# TC37XPD register map
Vendor: Infineon; Series: ATVMC; File version: 100
CPU: other r0p0, little endian, MPU, FPU, vendor SysTick, 4 interrupt priority bits
Registers are 32-bit, read-write, reset 0x0 unless marked. A register's access mark holds for its fields unless they carry their own. Offsets are from the block's base; [hi:lo] are bit positions; lines under a group give offsets from that group; {n}, {i} and the like mark numbered series.

## GTM (part 2 of 13)
Base 0xF0100000
0x400 BRC group
  {0x0+8j} SRC[{j}] (j=0..11) group
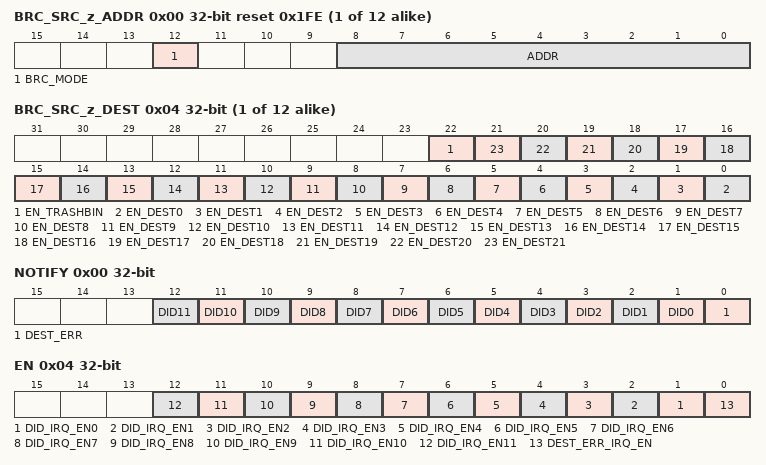
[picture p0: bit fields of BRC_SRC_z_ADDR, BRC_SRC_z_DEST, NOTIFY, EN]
    0x00 BRC_SRC_z_ADDR reset 0x1FE — BRC Read Address for Input Channel 0 resetvalue={Application Reset:0x1FE}
      [12] BRC_MODE — BRC MODE BRC Operation mode select. This bit field is only writable if channel is disabled.
      [8:0] ADDR — Source ARU address. Defines an ARU read address used as data source for input channel z. This bit field is only writable if channel is disabled.
    0x04 BRC_SRC_z_DEST — BRC Destination Channels for Input Channel 0 resetvalue={Application Reset:0x0}
      [22] EN_TRASHBIN — EN TRASHBIN Control trash bin functionality. When bit EN TRASHBIN is enabled bits 0 to 21 are ignored for this input channel. Therefore the bits 0 to 21 are set to zero 0 when trash bin functionality is enabled.
      [n] EN_DEST{n} (n=0..21) — Enable BRC destination address q. The bits 0 to 21 are cleared by auto correction mechanism if a destination channel is assigned to multiple source channels. When a BRC input channel is disabled all EN DESTq q 0...21 bits are reset to zero the internal states are reset to their reset value.
  0x60 IRQ group
    0x00 NOTIFY — BRC Interrupt Notification Register resetvalue={Application Reset:0x0}
      [n+1] DID{n} (n=0..11) — Data inconsistency occurred for channel x in MTM mode. This bit will be cleared on a CPU write access of value 1 . A read access leaves the bit unchanged.
      [0] DEST_ERR — Configuration error interrupt for BRC sub module. This bit will be cleared on a CPU write access of value 1 . As the bit is rw otherwise no clear. A read access leaves the bit unchanged.
    0x04 EN — BRC Interrupt Enable Register resetvalue={Application Reset:0x0}
      [n+1] DID_IRQ_EN{n} (n=0..11) — Enable DID interrupt for channel x
      [0] DEST_ERR_IRQ_EN — BRC DEST ERR IRQ interrupt enable
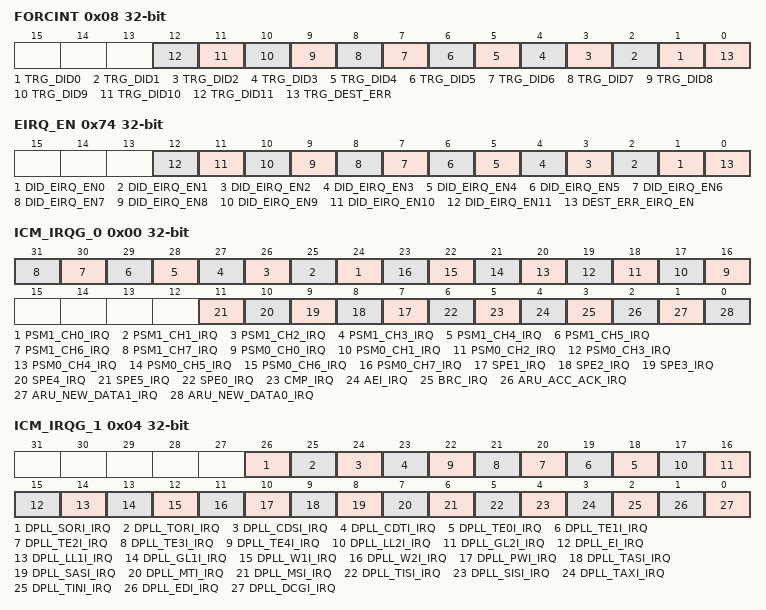
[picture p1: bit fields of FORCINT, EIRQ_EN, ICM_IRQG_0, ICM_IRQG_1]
    0x08 FORCINT — BRC Force Interrupt Register resetvalue={Application Reset:0x0}
      [n+1] TRG_DID{n} (n=0..11) — Trigger DID interrupt for channel x. This bit is cleared automatically after write. This bit is write protected by bit RF PROT of register GTM CTRL.
      [0] TRG_DEST_ERR — Trigger destination error interrupt. This bit is cleared automatically after write. This bit is write protected by bit RF PROT of register GTM CTRL.
    0x0C MODE — BRC Interrupt Mode Configuration Register resetvalue={Application Reset:0x0}
      [1:0] IRQ_MODE — IRQ mode selection. Note The interrupt modes are described in CROSSREFERENCE .
  0x70 RST — BRC Software Reset Register resetvalue={Application Reset:0x0}
    [0] RST — Software reset. This bit is cleared automatically after write by CPU. The channel registers are set to their reset values and channel operation is stopped immediately.
  0x74 EIRQ_EN — BRC Error Interrupt Enable Register resetvalue={Application Reset:0x0}
    [n+1] DID_EIRQ_EN{n} (n=0..11) — Enable DID interrupt for channel x
    [0] DEST_ERR_EIRQ_EN — BRC DEST ERR EIRQ error interrupt enable
0x600 ICM group
  0x00 IRQG group
    0x00 ICM_IRQG_0 ro — ICM Interrupt Group Register Covering Infrastructural and Safety Components ARU BRC AEI PSM0 PSM1 MAP CMP SPE resetvalue={Application Reset:0x0}
      [n+24] PSM1_CH{n}_IRQ (n=0..7) — PSM1 shared sub module channel 7 interrupt. See bit 0 and bit 6. Set this bit represents an OR function of the four interrupt sources FIFO EMPTY FIFO FULL FIFO LOWER WM or FIFO UPPER WM of FIFO instance 1 channel x.
      [n+16] PSM0_CH{n}_IRQ (n=0..7) — PSM0 shared sub module channel 7 interrupt. See bit 0 and bit 6. Set this bit represents an OR function of the four interrupt sources FIFO EMPTY FIFO FULL FIFO LOWER WM or FIFO UPPER WM of FIFO instance 0 channel x.
      [n+6] SPE{n}_IRQ (n=1..5) — SPE{n} shared sub module interrupt. See bit 0 and bit 6.
      [6] SPE0_IRQ — SPE0 shared sub module interrupt. Bit coding see bit 0. Set this bit represents an OR function of the five interrupt sources SPE NIPD SPE DCHG SPE PERR SPE BIS or SPE RCMP of SPE instance 0.
      [5] CMP_IRQ — CMP shared sub module interrupt. Bit coding see bit 0.
      [4] AEI_IRQ — AEI IRQ interrupt. Bit coding see bit 0. Set this bit represents an OR function of the seven interrupt sources AEI TO XPT AEI USP ADDR AEI IM ADDR AEI USP BE AEIM USP ADDR AEIM IM ADDR or AEIM USP BE .
      [3] BRC_IRQ — BRC shared sub module interrupt. Bit coding see bit 0.
      [2] ARU_ACC_ACK_IRQ — ARU ACC ACK interrupt. Bit coding see bit 0.
      [1] ARU_NEW_DATA1_IRQ — ARU NEW DATA1 interrupt. Bit coding see bit 0.
      [0] ARU_NEW_DATA0_IRQ — ARU NEW DATA0 interrupt. This bit is only set when the interrupt is enabled in the interrupt enable register of the corresponding sub module.
    0x04 ICM_IRQG_1 ro — ICM Interrupt Group Register Covering DPLL resetvalue={Application Reset:0x0}
      [26] DPLL_SORI_IRQ — DPLL calculated duration interrupt for state. Bit coding see bit 0.
      [25] DPLL_TORI_IRQ — DPLL calculated duration interrupt for state. Bit coding see bit 0.
      [24] DPLL_CDSI_IRQ — DPLL calculated duration interrupt for state. Bit coding see bit 0.
      [23] DPLL_CDTI_IRQ — DPLL calculated duration interrupt for trigger. Bit coding see bit 0.
      [n+18] DPLL_TE{n}I_IRQ (n=0..4) — TRIGGER event interrupt {n}. Bit coding see bit 0.
      [17] DPLL_LL2I_IRQ — Loss of lock interrupt for SUB INC2. Bit coding see bit 0.
      [16] DPLL_GL2I_IRQ — Get of lock interrupt for SUB INC2. Bit coding see bit 0.
      [15] DPLL_EI_IRQ — Error interrupt. Bit coding see bit 0.
      [14] DPLL_LL1I_IRQ — Loss of lock interrupt for SUB INC1. Bit coding see bit 0.
      [13] DPLL_GL1I_IRQ — Get of lock interrupt for SUB INC1. Bit coding see bit 0.
      [12] DPLL_W1I_IRQ — Write access to RAM region 1b or 1c interrupt. Bit coding see bit 0.
      [11] DPLL_W2I_IRQ — Write access to RAM region 2 interrupt. Bit coding see bit 0.
      [10] DPLL_PWI_IRQ — Plausibility window PVT violation interrupt of TRIGGER. Bit coding see bit 0.
      [9] DPLL_TASI_IRQ — TRIGGER active slope detected while NTI CNT is zero. Bit coding see bit 0.
      [8] DPLL_SASI_IRQ — STATE active slope detected. Bit coding see bit 0.
      [7] DPLL_MTI_IRQ — Missing TRIGGER interrupt. Bit coding see bit 0.
      [6] DPLL_MSI_IRQ — Missing STATE interrupt. Bit coding see bit 0.
      [5] DPLL_TISI_IRQ — TRIGGER inactive slope detected interrupt. Bit coding see bit 0.
      [4] DPLL_SISI_IRQ — STATE inactive slope detected interrupt. Bit coding see bit 0.
      [3] DPLL_TAXI_IRQ — TRIGGER maximum hold time THMA violation detected interrupt. Bit coding see bit 0.
      [2] DPLL_TINI_IRQ — TRIGGER minimum hold time THMI violation detected interrupt. Bit coding see bit 0.
      [1] DPLL_EDI_IRQ — DPLL enable disable interrupt. Set this bit represents an OR function of the two interrupt sources DPLL PDI or DPLL PEI. Bit coding see bit 0.
      [0] DPLL_DCGI_IRQ — TRIGGER direction change detected. This bit is only set when the interrupt is enabled in the interrupt enable register of the corresponding sub module.
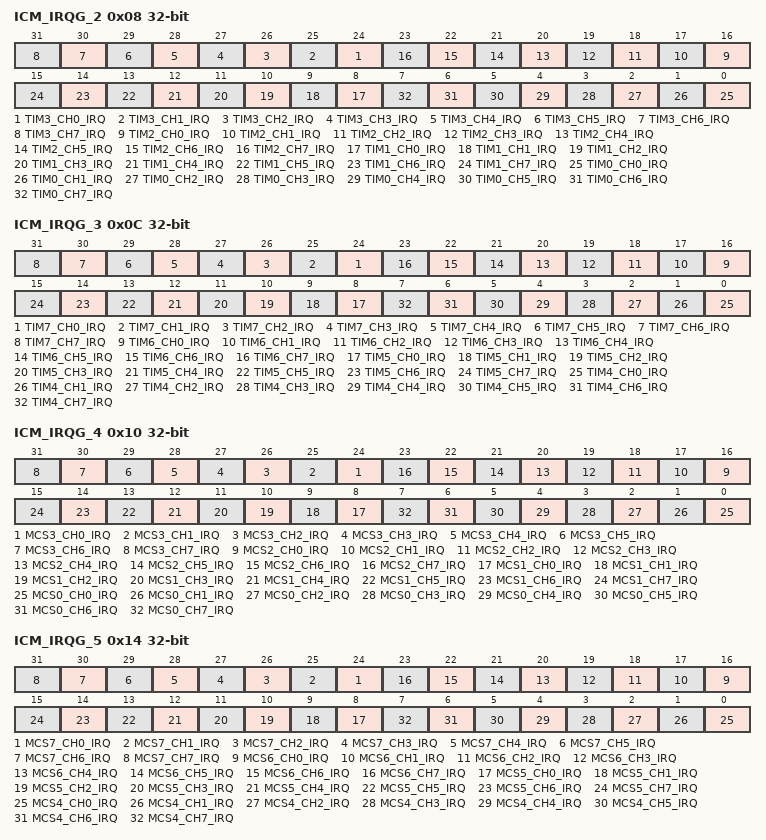
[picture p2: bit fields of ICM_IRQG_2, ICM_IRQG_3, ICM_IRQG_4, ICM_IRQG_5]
    0x08 ICM_IRQG_2 ro — ICM Interrupt Group Register Covering TIM0 TIM1 TIM2 TIM3 resetvalue={Application Reset:0x0}
      [n+24] TIM3_CH{n}_IRQ (n=0..7) — TIM2 shared interrupt channel 7. This bit is only set when the interrupt is enabled in the interrupt enable register of the corresponding sub module. Set this bit represents an OR function of the six interrupt sources NEWVALx IRQ ECNTOFLx IRQ CNTOFLx IRQ GPRXOFLx IRQ GLITCHDETx IRQ or TODETx IRQ of TIM instance 3 channel x.
      [n+16] TIM2_CH{n}_IRQ (n=0..7) — TIM2 shared interrupt channel 7. This bit is only set when the interrupt is enabled in the interrupt enable register of the corresponding sub module. Set this bit represents an OR function of the six interrupt sources NEWVALx IRQ ECNTOFLx IRQ CNTOFLx IRQ GPRXOFLx IRQ GLITCHDETx IRQ or TODETx IRQ of TIM instance 2 channel x.
      [n+8] TIM1_CH{n}_IRQ (n=0..7) — TIM1 shared interrupt channel 7. This bit is only set when the interrupt is enabled in the interrupt enable register of the corresponding sub module. Set this bit represents an OR function of the six interrupt sources NEWVALx IRQ ECNTOFLx IRQ CNTOFLx IRQ GPRXOFLx IRQ GLITCHDETx IRQ or TODETx IRQ of TIM instance 1 channel x.
      [n] TIM0_CH{n}_IRQ (n=0..7) — TIM0 shared interrupt channel 7. This bit is only set when the interrupt is enabled in the interrupt enable register of the corresponding sub module. Set this bit represents an OR function of the six interrupt sources NEWVALx IRQ ECNTOFLx IRQ CNTOFLx IRQ GPRXOFLx IRQ GLITCHDETx IRQ or TODETx IRQ of TIM instance 0 channel x.
    0x0C ICM_IRQG_3 ro — ICM Interrupt Group Register Covering TIM4 TIM5 TIM6 TIM7 resetvalue={Application Reset:0x0}
      [n+24] TIM7_CH{n}_IRQ (n=0..7) — TIM7 shared interrupt channel 7. This bit is only set when the interrupt is enabled in the interrupt enable register of the corresponding sub module. Set this bit represents an OR function of the six interrupt sources NEWVALx IRQ ECNTOFLx IRQ CNTOFLx IRQ GPRXOFLx IRQ GLITCHDETx IRQ or TODETx IRQ of TIM instance 7 channel x.
      [n+16] TIM6_CH{n}_IRQ (n=0..7) — TIM6 shared interrupt channel 7. This bit is only set when the interrupt is enabled in the interrupt enable register of the corresponding sub module. Set this bit represents an OR function of the six interrupt sources NEWVALx IRQ ECNTOFLx IRQ CNTOFLx IRQ GPRXOFLx IRQ GLITCHDETx IRQ or TODETx IRQ of TIM instance 6 channel x.
      [n+8] TIM5_CH{n}_IRQ (n=0..7) — TIM5 shared interrupt channel 7. This bit is only set when the interrupt is enabled in the interrupt enable register of the corresponding sub module. Set this bit represents an OR function of the six interrupt sources NEWVALx IRQ ECNTOFLx IRQ CNTOFLx IRQ GPRXOFLx IRQ GLITCHDETx IRQ or TODETx IRQ of TIM instance 5 channel x.
      [n] TIM4_CH{n}_IRQ (n=0..7) — TIM4 shared interrupt channel 7. This bit is only set when the interrupt is enabled in the interrupt enable register of the corresponding sub module. Set this bit represents an OR function of the six interrupt sources NEWVALx IRQ ECNTOFLx IRQ CNTOFLx IRQ GPRXOFLx IRQ GLITCHDETx IRQ or TODETx IRQ of TIM instance 4 channel x.
    0x10 ICM_IRQG_4 ro — ICM Interrupt Group Register Covering MCS0 to MCS3 Sub Modules resetvalue={Application Reset:0x0}
      [n+24] MCS3_CH{n}_IRQ (n=0..7) — MCS3 channel 7 interrupt. This bit is only set when the interrupt is enabled in the interrupt enable register of the corresponding sub module. Set this bit represents an OR function of the three interrupt sources MCS IRQ STK ERR IRQ or ERR IRQ of MCS instance 3 channel x.
      [n+16] MCS2_CH{n}_IRQ (n=0..7) — MCS2 channel 7 interrupt. This bit is only set when the interrupt is enabled in the interrupt enable register of the corresponding sub module. Set this bit represents an OR function of the three interrupt sources MCS IRQ STK ERR IRQ or ERR IRQ of MCS instance 2 channel x.
      [n+8] MCS1_CH{n}_IRQ (n=0..7) — MCS1 channel 7 interrupt. This bit is only set when the interrupt is enabled in the interrupt enable register of the corresponding sub module. Set this bit represents an OR function of the three interrupt sources MCS IRQ STK ERR IRQ or ERR IRQ of MCS instance 1 channel x.
      [n] MCS0_CH{n}_IRQ (n=0..7) — MCS0 channel 7 interrupt. This bit is only set when the interrupt is enabled in the interrupt enable register of the corresponding sub module. Set this bit represents an OR function of the three interrupt sources MCS IRQ STK ERR IRQ or ERR IRQ of MCS instance 0 channel x.
    0x14 ICM_IRQG_5 ro — ICM Interrupt Group Register Covering MCS4 to MCS6 Sub Modules resetvalue={Application Reset:0x0}
      [n+24] MCS7_CH{n}_IRQ (n=0..7) — MCS7 channel 7 interrupt. This bit is only set when the interrupt is enabled in the interrupt enable register of the corresponding sub module. Set this bit represents an OR function of the three interrupt sources MCS IRQ STK ERR IRQ or ERR IRQ of MCS instance 7 channel x.
      [n+16] MCS6_CH{n}_IRQ (n=0..7) — MCS6 channel 7 interrupt. This bit is only set when the interrupt is enabled in the interrupt enable register of the corresponding sub module. Set this bit represents an OR function of the three interrupt sources MCS IRQ STK ERR IRQ or ERR IRQ of MCS instance 6 channel x.
      [n+8] MCS5_CH{n}_IRQ (n=0..7) — MCS5 channel 7 interrupt. This bit is only set when the interrupt is enabled in the interrupt enable register of the corresponding sub module. Set this bit represents an OR function of the three interrupt sources MCS IRQ STK ERR IRQ or ERR IRQ of MCS instance 5 channel x.
      [n] MCS4_CH{n}_IRQ (n=0..7) — MCS4 channel 7 interrupt. This bit is only set when the interrupt is enabled in the interrupt enable register of the corresponding sub module. Set this bit represents an OR function of the three interrupt sources MCS IRQ STK ERR IRQ or ERR IRQ of MCS instance 4 channel x.
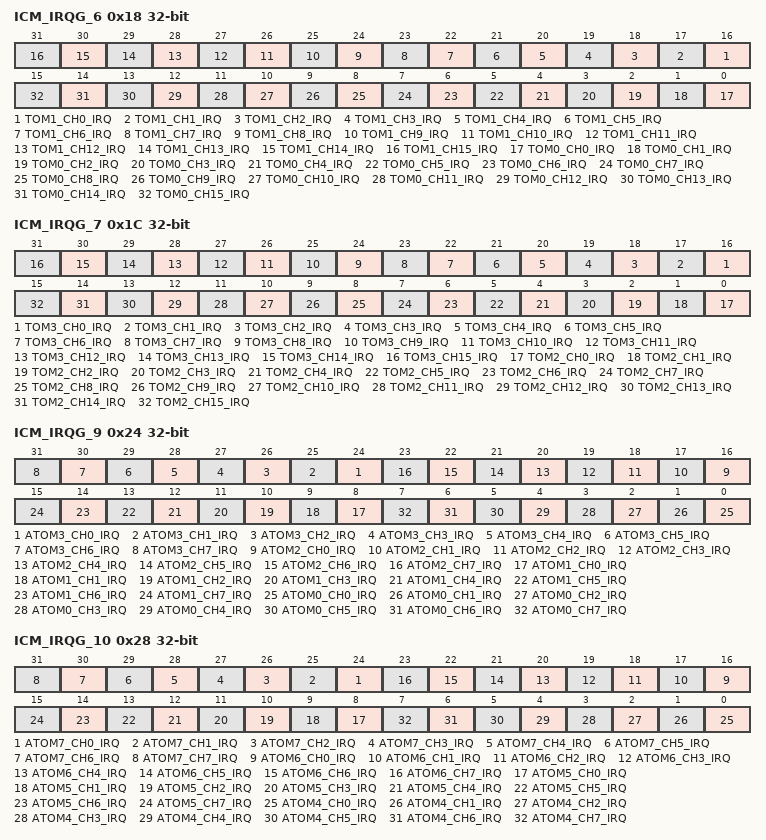
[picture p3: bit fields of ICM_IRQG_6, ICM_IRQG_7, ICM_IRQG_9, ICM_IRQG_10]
    0x18 ICM_IRQG_6 ro — ICM Interrupt Group Register Covering GTM Output Sub Modules TOM0 to TOM1 resetvalue={Application Reset:0x0}
      [n+16] TOM1_CH{n}_IRQ (n=0..15) — TOM1 channel 15 shared interrupt. This bit is only set when the interrupt is enabled in the interrupt enable register of the corresponding sub module. Set this bit represents an OR function of the two interrupt sources TOM CCU0TCx IRQ or TOM CCU1TCx IRQ of TOM instance 1 channel x.
      [n] TOM0_CH{n}_IRQ (n=0..15) — TOM0 channel 15 shared interrupt. This bit is only set when the interrupt is enabled in the interrupt enable register of the corresponding sub module. Set this bit represents an OR function of the two interrupt sources TOM CCU0TCx IRQ or TOM CCU1TCx IRQ of TOM instance 0 channel x.
    0x1C ICM_IRQG_7 ro — ICM Interrupt Group Register Covering GTM Output Sub Modules TOM2 to TOM3 resetvalue={Application Reset:0x0}
      [n+16] TOM3_CH{n}_IRQ (n=0..15) — TOM3 channel 15 shared interrupt. This bit is only set when the interrupt is enabled in the interrupt enable register of the corresponding sub module. Set this bit represents an OR function of the two interrupt sources TOM CCU0TCx IRQ or TOM CCU1TCx IRQ of TOM instance 3 channel x.
      [n] TOM2_CH{n}_IRQ (n=0..15) — TOM2 channel 15 shared interrupt. This bit is only set when the interrupt is enabled in the interrupt enable register of the corresponding sub module. Set this bit represents an OR function of the two interrupt sources TOM CCU0TCx IRQ or TOM CCU1TCx IRQ of TOM instance 2 channel x.
    0x24 ICM_IRQG_9 ro — ICM Interrupt Group Register Covering GTM Output Sub Modules ATOM0 ATOM1 ATOM2 and ATOM3 resetvalue={Application Reset:0x0}
      [n+24] ATOM3_CH{n}_IRQ (n=0..7) — ATOM3 channel 7 shared interrupt. This bit is only set when the interrupt is enabled in the interrupt enable register of the corresponding sub module. Set this bit represents an OR function of the two interrupt sources CCU0TCx IRQ or CCU1TCx IRQ of ATOM instance 3 channel x.
      [n+16] ATOM2_CH{n}_IRQ (n=0..7) — ATOM2 channel 7 shared interrupt. This bit is only set when the interrupt is enabled in the interrupt enable register of the corresponding sub module. Set this bit represents an OR function of the two interrupt sources CCU0TCx IRQ or CCU1TCx IRQ of ATOM instance 2 channel x.
      [n+8] ATOM1_CH{n}_IRQ (n=0..7) — ATOM1 channel 7 shared interrupt. This bit is only set when the interrupt is enabled in the interrupt enable register of the corresponding sub module. Set this bit represents an OR function of the two interrupt sources CCU0TCx IRQ or CCU1TCx IRQ of ATOM instance 1 channel x.
      [n] ATOM0_CH{n}_IRQ (n=0..7) — ATOM0 channel 7 shared interrupt. This bit is only set when the interrupt is enabled in the interrupt enable register of the corresponding sub module. Set this bit represents an OR function of the two interrupt sources CCU0TCx IRQ or CCU1TCx IRQ of ATOM instance 0 channel x.
    0x28 ICM_IRQG_10 ro — ICM Interrupt Group Register Covering GTM Output Sub Modules ATOM4 to ATOM7 resetvalue={Application Reset:0x0}
      [n+24] ATOM7_CH{n}_IRQ (n=0..7) — ATOM7 channel 7 shared interrupt. This bit is only set when the interrupt is enabled in the interrupt enable register of the corresponding sub module. Set this bit represents an OR function of the two interrupt sources CCU0TCx IRQ or CCU1TCx IRQ of ATOM instance 7 channel x.
      [n+16] ATOM6_CH{n}_IRQ (n=0..7) — ATOM6 channel 7 shared interrupt. This bit is only set when the interrupt is enabled in the interrupt enable register of the corresponding sub module. Set this bit represents an OR function of the two interrupt sources CCU0TCx IRQ or CCU1TCx IRQ of ATOM instance 6 channel x.
      [n+8] ATOM5_CH{n}_IRQ (n=0..7) — ATOM5 channel 7 shared interrupt. This bit is only set when the interrupt is enabled in the interrupt enable register of the corresponding sub module. Set this bit represents an OR function of the two interrupt sources CCU0TCx IRQ or CCU1TCx IRQ of ATOM instance 5 channel x.
      [n] ATOM4_CH{n}_IRQ (n=0..7) — ATOM4 channel 7 shared interrupt. This bit is only set when the interrupt is enabled in the interrupt enable register of the corresponding sub module. Set this bit represents an OR function of the two interrupt sources CCU0TCx IRQ or CCU1TCx IRQ of ATOM instance 4 channel x.
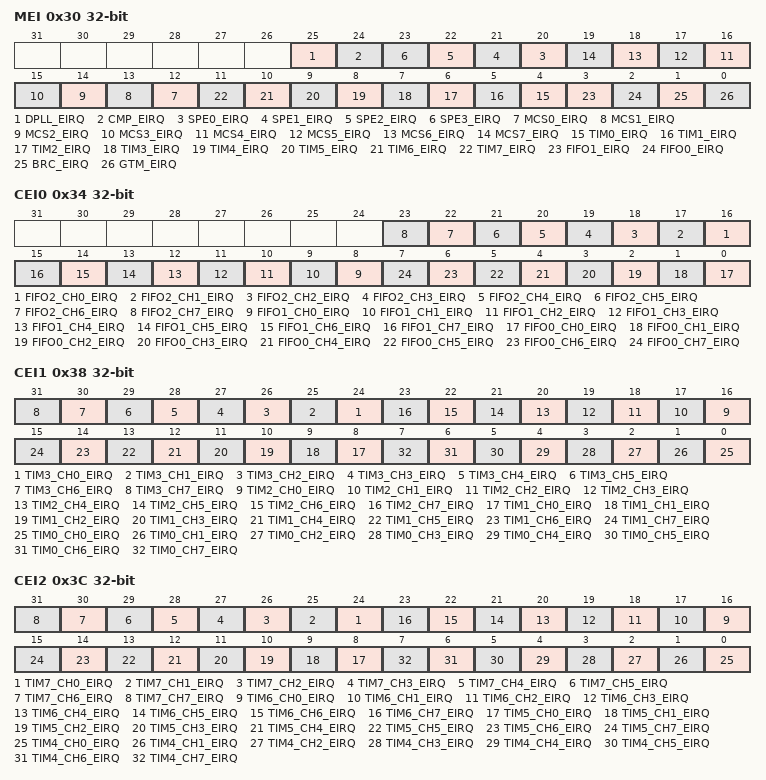
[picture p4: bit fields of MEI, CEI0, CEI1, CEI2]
    0x30 MEI ro — ICM Interrupt Group Register for Module Error Interrupt Information resetvalue={Application Reset:0x0}
      [25] DPLL_EIRQ — DPLL error interrupt. Bit coding see bit 0.
      [24] CMP_EIRQ — CMP error interrupt. Bit coding see bit 0.
      [n+20] SPE{n}_EIRQ (n=0..3) — SPE3 error interrupt. Bit coding see bit 0.
      [n+12] MCS{n}_EIRQ (n=0..7) — MCS7 error interrupt. Bit coding see bit 0.
      [n+4] TIM{n}_EIRQ (n=0..7) — TIM7 error interrupt. Bit coding see bit 0.
      [3] FIFO1_EIRQ — FIFO1 error interrupt. Bit coding see bit 0.
      [2] FIFO0_EIRQ — FIFO0 error interrupt. Bit coding see bit 0.
      [1] BRC_EIRQ — BRC error interrupt. Bit coding see bit 0.
      [0] GTM_EIRQ — AEI Error interrupt request. This bit is only set when the error interrupt is enabled in the error interrupt enable register of the corresponding sub module. Set this bit represents an OR function of the seven interrupt sources AEI TO XPT EIRQ AEI USP ADDR EIRQ AEI IM ADDR EIRQ AEI USP BE EIRQ AEIM USP ADDR EIRQ AEIM IM ADDR EIRQ or AEIM USP BE EIRQ .
    0x34 CEI0 ro — ICM Interrupt Group Register 0 for Channel Error Interrupt Information resetvalue={Application Reset:0x0}
      [n+16] FIFO2_CH{n}_EIRQ (n=0..7) — FIFO2 channel 7 error interrupt. This bit is only set when the error interrupt is enabled in the error interrupt enable register of the corresponding sub module.
      [n+8] FIFO1_CH{n}_EIRQ (n=0..7) — FIFO1 channel 7 error interrupt. This bit is only set when the error interrupt is enabled in the error interrupt enable register of the corresponding sub module.
      [n] FIFO0_CH{n}_EIRQ (n=0..7) — FIFO0 channel 7 error interrupt. This bit is only set when the error interrupt is enabled in the error interrupt enable register of the corresponding sub module.
    0x38 CEI1 ro — ICM Interrupt Group Register 1 for Channel Error Interrupt Information resetvalue={Application Reset:0x0}
      [n+24] TIM3_CH{n}_EIRQ (n=0..7) — TIM3 channel 7 error interrupt. This bit is only set when the error interrupt is enabled in the error interrupt enable register of the corresponding sub module.
      [n+16] TIM2_CH{n}_EIRQ (n=0..7) — TIM2 channel 7 error interrupt. This bit is only set when the error interrupt is enabled in the error interrupt enable register of the corresponding sub module.
      [n+8] TIM1_CH{n}_EIRQ (n=0..7) — TIM1 channel 7 error interrupt. This bit is only set when the error interrupt is enabled in the error interrupt enable register of the corresponding sub module.
      [n] TIM0_CH{n}_EIRQ (n=0..7) — TIM0 channel 7 error interrupt. This bit is only set when the error interrupt is enabled in the error interrupt enable register of the corresponding sub module.
    0x3C CEI2 ro — ICM Interrupt Group Register 2 for Channel Error Interrupt Information resetvalue={Application Reset:0x0}
      [n+24] TIM7_CH{n}_EIRQ (n=0..7) — TIM7 channel 7 error interrupt. This bit is only set when the error interrupt is enabled in the error interrupt enable register of the corresponding sub module.
      [n+16] TIM6_CH{n}_EIRQ (n=0..7) — TIM6 channel 7 error interrupt. This bit is only set when the error interrupt is enabled in the error interrupt enable register of the corresponding sub module.
      [n+8] TIM5_CH{n}_EIRQ (n=0..7) — TIM5 channel 7 error interrupt. This bit is only set when the error interrupt is enabled in the error interrupt enable register of the corresponding sub module.
      [n] TIM4_CH{n}_EIRQ (n=0..7) — TIM4 channel 7 error interrupt. This bit is only set when the error interrupt is enabled in the error interrupt enable register of the corresponding sub module.
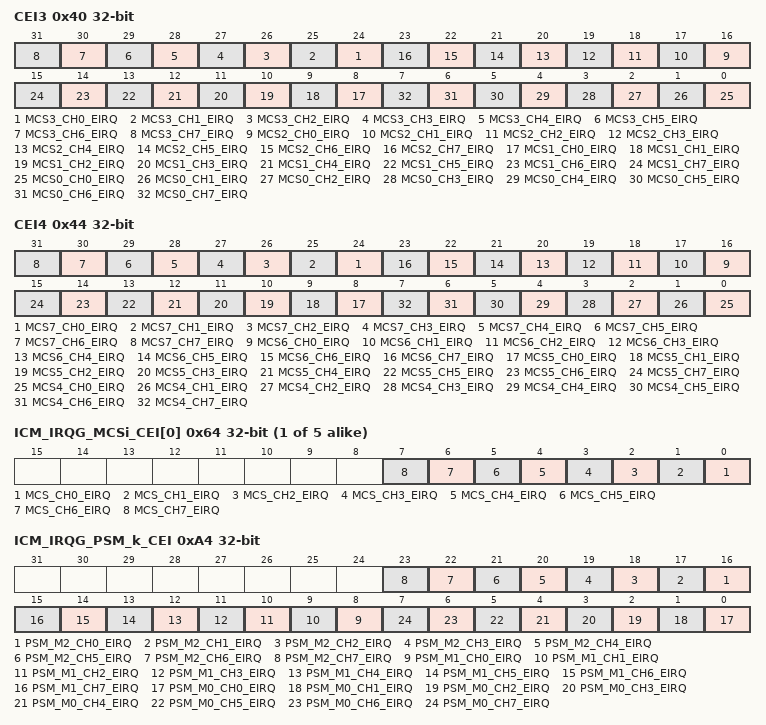
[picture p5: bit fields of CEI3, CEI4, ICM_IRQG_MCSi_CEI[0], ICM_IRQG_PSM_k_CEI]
    0x40 CEI3 ro — ICM Interrupt Group Register 3 for Channel Error Interrupt Information resetvalue={Application Reset:0x0}
      [n+24] MCS3_CH{n}_EIRQ (n=0..7) — MCS3 channel 7 error interrupt. This bit is only set when the error interrupt is enabled in the error interrupt enable register of the corresponding sub module.
      [n+16] MCS2_CH{n}_EIRQ (n=0..7) — MCS2 channel 7 error interrupt. This bit is only set when the error interrupt is enabled in the error interrupt enable register of the corresponding sub module.
      [n+8] MCS1_CH{n}_EIRQ (n=0..7) — MCS1 channel 7 error interrupt. This bit is only set when the error interrupt is enabled in the error interrupt enable register of the corresponding sub module.
      [n] MCS0_CH{n}_EIRQ (n=0..7) — MCS0 channel 7 error interrupt. This bit is only set when the error interrupt is enabled in the error interrupt enable register of the corresponding sub module.
    0x44 CEI4 ro — ICM Interrupt Group Register 4 for Channel Error Interrupt Information resetvalue={Application Reset:0x0}
      [n+24] MCS7_CH{n}_EIRQ (n=0..7) — MCS7 channel 7 error interrupt. This bit is only set when the error interrupt is enabled in the error interrupt enable register of the corresponding sub module.
      [n+16] MCS6_CH{n}_EIRQ (n=0..7) — MCS6 channel 7 error interrupt. This bit is only set when the error interrupt is enabled in the error interrupt enable register of the corresponding sub module.
      [n+8] MCS5_CH{n}_EIRQ (n=0..7) — MCS5 channel 7 error interrupt. This bit is only set when the error interrupt is enabled in the error interrupt enable register of the corresponding sub module.
      [n] MCS4_CH{n}_EIRQ (n=0..7) — MCS4 channel 7 error interrupt. This bit is only set when the error interrupt is enabled in the error interrupt enable register of the corresponding sub module.
    {0x64+4k} ICM_IRQG_MCSi_CEI[{k}] (k=0..4) ro — ICM Interrupt Group MCS 0 for Channel Error Interrupt information resetvalue={Application Reset:0x0}
      [n] MCS_CH{n}_EIRQ (n=0..7) — MCS channel 7 error interrupt. This bit is only set when the interrupt is enabled in the interrupt enable register of the corresponding sub module.
    0xA4 ICM_IRQG_PSM_k_CEI ro — ICM Interrupt Group PSM 0 for Channel Error Interrupt information of FIFO0 FIFO1 FIFO2 resetvalue={Application Reset:0x0}
      [n+16] PSM_M2_CH{n}_EIRQ (n=0..7) — PSM2 channel 7 error interrupt m 4 0 0 . This bit is only set when the error interrupt is enabled in the error interrupt enable register of the corresponding sub module.
      [n+8] PSM_M1_CH{n}_EIRQ (n=0..7) — PSM1 channel 7 error interrupt m 4 0 0 . This bit is only set when the error interrupt is enabled in the error interrupt enable register of the corresponding sub module.
      [n] PSM_M0_CH{n}_EIRQ (n=0..7) — PSM0 channel 7 error interrupt m 4 0 0 . This bit is only set when the error interrupt is enabled in the error interrupt enable register of the corresponding sub module.
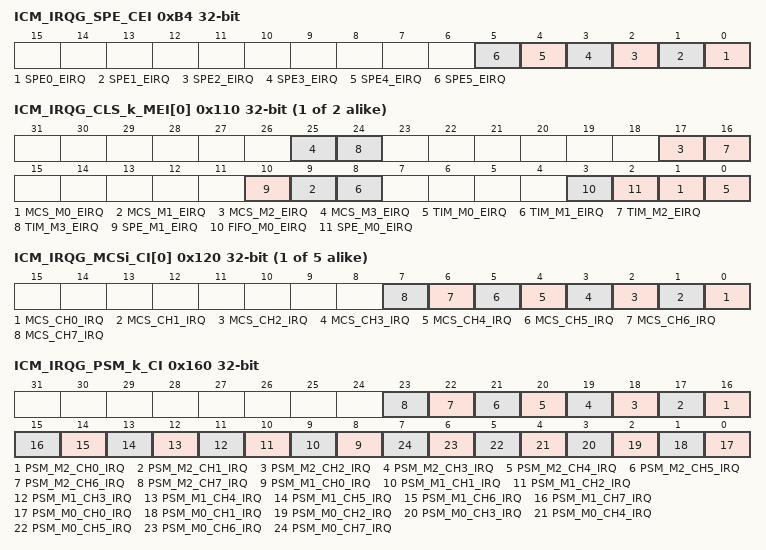
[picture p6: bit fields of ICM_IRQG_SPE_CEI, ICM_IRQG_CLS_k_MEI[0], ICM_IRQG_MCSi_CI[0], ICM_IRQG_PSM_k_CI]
    0xB4 ICM_IRQG_SPE_CEI ro — ICM Interrupt Group SPE for Module Error Interrupt Information resetvalue={Application Reset:0x0}
      [n] SPE{n}_EIRQ (n=0..5) — SPE channel 5 error interrupt. This bit is only set when the interrupt is enabled in the interrupt enable register of the corresponding sub module.
    {0x110+4k} ICM_IRQG_CLS_k_MEI[{k}] (k=0..1) ro — ICM Interrupt Group k for Module Error Interrupt Information for each TIMm MCSm SPEm FIFOm resetvalue={Application Reset:0x0}
      [8n+1] MCS_M{n}_EIRQ (n=0..3) — Error interrupt MCSm EIRQ m 4 0 3 . Coding see bit 0.
      [8n] TIM_M{n}_EIRQ (n=0..3) — Error interrupt TIMm EIRQ m 4 0 3 . This bit is only set when the error interrupt is enabled in the error interrupt enable register of the corresponding sub module.
      [10] SPE_M1_EIRQ — Error interrupt SPEm EIRQ m 4 0 3 . Coding see bit 0.
      [3] FIFO_M0_EIRQ — Error interrupt FIFOm EIRQ m 4 0 3 . Coding see bit 0.
      [2] SPE_M0_EIRQ — Error interrupt SPEm EIRQ m 4 0 3 . Coding see bit 0.
    {0x120+4k} ICM_IRQG_MCSi_CI[{k}] (k=0..4) ro — ICM Interrupt Group MCS 0 for Channel Interrupt Information resetvalue={Application Reset:0x0}
      [n] MCS_CH{n}_IRQ (n=0..7) — MCS channel 7 interrupt. This bit is only set when the interrupt is enabled in the interrupt enable register of the corresponding sub module.
    0x160 ICM_IRQG_PSM_k_CI ro — ICM Interrupt Group PSM 0 for Channel Interrupt Information of FIFO0 FIFO1 FIFO2 resetvalue={Application Reset:0x0}
      [n+16] PSM_M2_CH{n}_IRQ (n=0..7) — PSM2 channel 7 shared interrupt m 4 0 0 . This bit is only set when the interrupt is enabled in the interrupt enable register of the corresponding sub module. Set this bit represents an OR function of the four interrupt sources FIFO EMPTY FIFO FULL FIFO LOWER WM or FIFO UPPER WM of FIFO instance 2 channel x.
      [n+8] PSM_M1_CH{n}_IRQ (n=0..7) — PSM1 channel 7 shared interrupt m 4 0 0 . This bit is only set when the interrupt is enabled in the interrupt enable register of the corresponding sub module. Set this bit represents an OR function of the four interrupt sources FIFO EMPTY FIFO FULL FIFO LOWER WM or FIFO UPPER WM of FIFO instance 1 channel x.
      [n] PSM_M0_CH{n}_IRQ (n=0..7) — PSM0 channel 7 shared interrupt m 4 0 0 . This bit is only set when the interrupt is enabled in the interrupt enable register of the corresponding sub module. Set this bit represents an OR function of the four interrupt sources FIFO EMPTY FIFO FULL FIFO LOWER WM or FIFO UPPER WM of FIFO instance 0 channel x.
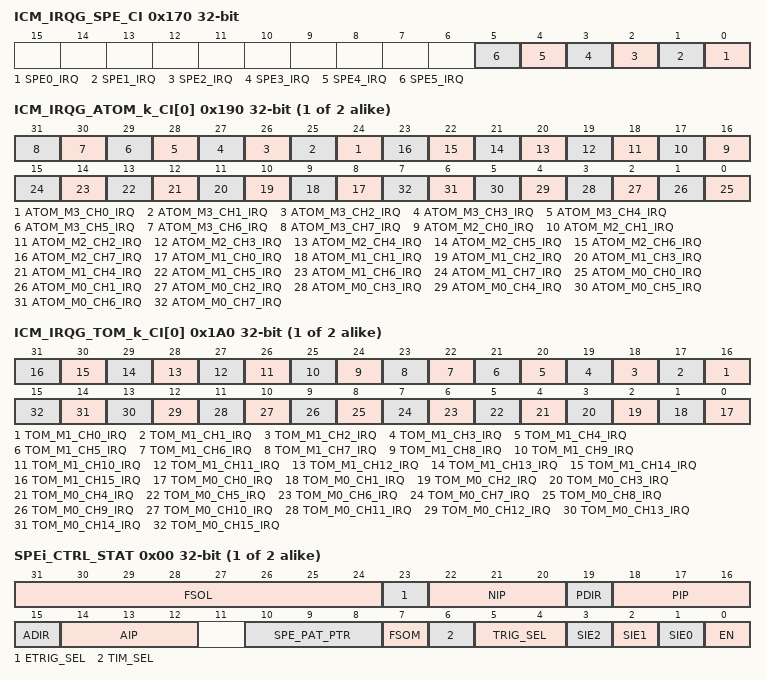
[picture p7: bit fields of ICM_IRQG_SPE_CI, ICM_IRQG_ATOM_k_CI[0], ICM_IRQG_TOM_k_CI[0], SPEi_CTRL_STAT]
    0x170 ICM_IRQG_SPE_CI ro — ICM Interrupt Group SPE for Module Interrupt Information resetvalue={Application Reset:0x0}
      [n] SPE{n}_IRQ (n=0..5) — SPE channel 5 interrupt. This bit is only set when the interrupt is enabled in the interrupt enable register of the corresponding sub module.
    {0x190+4k} ICM_IRQG_ATOM_k_CI[{k}] (k=0..1) ro — ICM Interrupt Group ATOM 0 for Channel Interrupt Information of ATOMm resetvalue={Application Reset:0x0}
      [n+24] ATOM_M3_CH{n}_IRQ (n=0..7) — ATOMm channel 7 interrupt m 4 0 3 . This bit is only set when the interrupt is enabled in the interrupt enable register of the corresponding sub module. Set this bit represents an OR function of the two interrupt sources CCU0TCx IRQ or CCU1TCx IRQ of ATOM instance 2 channel x.
      [n+16] ATOM_M2_CH{n}_IRQ (n=0..7) — ATOMm channel 7 interrupt m 4 0 2 . This bit is only set when the interrupt is enabled in the interrupt enable register of the corresponding sub module. Set this bit represents an OR function of the two interrupt sources CCU0TCx IRQ or CCU1TCx IRQ of ATOM instance 2 channel x.
      [n+8] ATOM_M1_CH{n}_IRQ (n=0..7) — ATOMm channel 7 interrupt m 4 0 1 . This bit is only set when the interrupt is enabled in the interrupt enable register of the corresponding sub module. Set this bit represents an OR function of the two interrupt sources CCU0TCx IRQ or CCU1TCx IRQ of ATOM instance 1 channel x.
      [n] ATOM_M0_CH{n}_IRQ (n=0..7) — ATOMm channel 7 interrupt m 4 0 0 . This bit is only set when the interrupt is enabled in the interrupt enable register of the corresponding sub module. Set this bit represents an OR function of the two interrupt sources CCU0TCx IRQ or CCU1TCx IRQ of ATOM instance 0 channel x.
    {0x1A0+4k} ICM_IRQG_TOM_k_CI[{k}] (k=0..1) ro — ICM Interrupt Group TOM 0 for Channel Interrupt Information of TOMm resetvalue={Application Reset:0x0}
      [n+16] TOM_M1_CH{n}_IRQ (n=0..15) — TOMm channel 15 interrupt m 2 0 1 . This bit is only set when the interrupt is enabled in the interrupt enable register of the corresponding sub module. Set this bit represents an OR function of the two interrupt sources TOM CCU0TCx IRQ or TOM CCU1TCx IRQ of TOM instance 1 channel x.
      [n] TOM_M0_CH{n}_IRQ (n=0..15) — TOMm channel 15 interrupt m 2 0 0 . This bit is only set when the interrupt is enabled in the interrupt enable register of the corresponding sub module. Set this bit represents an OR function of the two interrupt sources TOM CCU0TCx IRQ or TOM CCU1TCx IRQ of TOM instance 0 channel x.
{0x800+0x80*i} SPE[{i}] (i=0..1) group
  0x00 SPEi_CTRL_STAT access per field — SPE0 Control Status Register resetvalue={Application Reset:0x0}
    [31:24] FSOL rw — Fast Shutoff Level for TOM i channel 0 to 7
    [23] ETRIG_SEL rw — Extended TRIG SEL. Extended trigger selection. Details described in TRIG SEL bit field. ETRIG SEL 0 ETRIG SEL 1 00 SPE i NIPD selected TOM CH6 TRIG CCU1 selected 01 TOM CH0 TRIG CCU0 selected TOM CH7 TRIG CCU1 selected 10 TOM CH0 TRIG CCU1 selected TOM CH8 TRIG CCU1 selected 11 TOM CH2 TRIG CCU1 selected TOM CH9 TRIG CCU1 selected
    [22:20] NIP ro — New input pattern that was detected. This bit field mirrors the new input pattern. SPE internal functionality is triggered on each change of this bit field.
    [19] PDIR rw — Previous rotation direction
    [18:16] PIP rw — Previous input pattern that was detected by a regular input pattern change
    [15] ADIR rw — Actual rotation direction
    [14:12] AIP rw — Actual input pattern that was detected by a regular input pattern change
    [10:8] SPE_PAT_PTR rw — Pattern selector for TOM output signals. Actual index into the SPE i OUT PAT x register table. Each register SPE i OUT PAT x is fixed assigned to one bit field IPx PAT of register SPE i PAT. Thus the pointer SPE i PAT PTR represents an index to the selected SPE i OUT PAT x register as well as the actual detected input pattern IPx PAT.
    [7] FSOM rw — Fast Shutoff Mode
    [6] TIM_SEL rw — Select TIM input signal. The GTM supports up to 6 SPE modules.SPE0
    [5:4] TRIG_SEL rw — Select trigger input signal. ETRIG SEL 0 ETRIG SEL 1 In case of ETRIG SEL 1 according to selected TOM CH x TRIG CCU1 signal the configuration bits SPE TRIG and OSM of register TOM CH x CTRL have to be set in same TOM channel x to enable the trigger signal generation in one shot mode.
    [3] SIE2 rw — SPE Input enable for TIM CHz 48 . Coding see bit 1.
    [2] SIE1 rw — SPE Input enable for TIM CHy 48 . Coding see bit 1.
    [1] SIE0 rw — SPE Input enable for TIM CHx 48 . When the input is disabled a 0 signal is sampled for this input. However the bit field NIP of this register shows the true value of the input signal.
    [0] EN rw — SPE Submodule enable
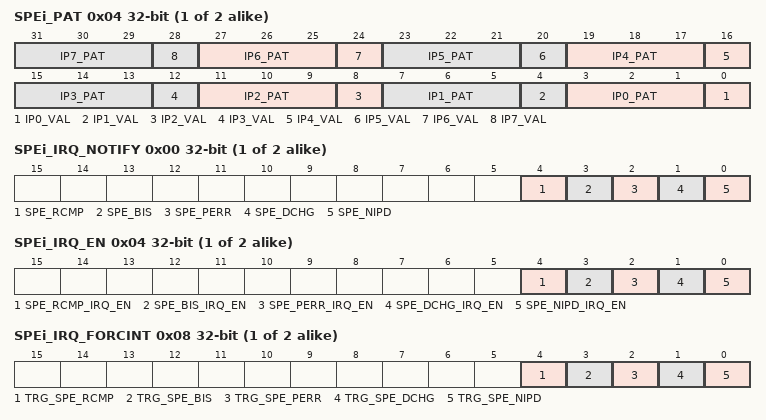
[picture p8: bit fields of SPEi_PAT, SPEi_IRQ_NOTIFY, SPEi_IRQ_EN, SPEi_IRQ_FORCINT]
  0x04 SPEi_PAT — SPE0 Input Pattern Definition Register resetvalue={Application Reset:0x0}
    [4n+3:4n+1] IP{n}_PAT (n=0..7) — Input pattern 7 IP7 PAT. Bit field defines the input pattern z of the SPE input signals. Bit 1 defines the TIM i CHx 48 input signal. Bit 2 defines the TIM i CHy 48 input signal. Bit 3 defines the TIM i CHz 48 input signal.
    [4n] IP{n}_VAL (n=0..7) — Input pattern 7 is a valid pattern
  {0x8+4j} OUT_PAT[{j}] (j=0..7) — SPE0 Output Definition Register z resetvalue={Application Reset:0x0}
    [15:0] SPE_OUT_PAT — SPE output control value for TOM CH0 to TOM CH7. SPE OUT PAT n 1 n defines output select signal of TOM i CH n with n 0...7 Current output control selection for SPE i OUT 0..7 .
  0x28 SPEi_OUT_CTRL — SPE0 Output Control Register resetvalue={Application Reset:0x0}
    [15:0] SPE_OUT_CTRL — SPE output control value for TOM CH0 to TOM CH7. SPE OUT CTRL n 1 n defines output select signal of TOM CHn. Current output control selection for SPE i OUT 0..7 .
  0x2C IRQ group
    0x00 SPEi_IRQ_NOTIFY — SPE0 Interrupt Notification Register resetvalue={Application Reset:0x0}
      [4] SPE_RCMP — SPE revolution counter match event. Coding see bit 0.
      [3] SPE_BIS — Bouncing input signal detected. Coding see bit 0.
      [2] SPE_PERR — Wrong or invalid pattern detected at input. Coding see bit 0.
      [1] SPE_DCHG — SPE DIR bit changed on behalf of new input pattern. Coding see bit 0.
      [0] SPE_NIPD — New input pattern interrupt occurred. This bit will be cleared on a CPU write access of value 1. As the bit is rw otherwise no clear. A read access leaves the bit unchanged.
    0x04 SPEi_IRQ_EN — SPE0 Interrupt Enable Register resetvalue={Application Reset:0x0}
      [4] SPE_RCMP_IRQ_EN — SPE RCMP IRQ interrupt enable. Coding see bit 0.
      [3] SPE_BIS_IRQ_EN — SPE BIS IRQ interrupt enable. Coding see bit 0.
      [2] SPE_PERR_IRQ_EN — SPE PERR IRQ interrupt enable. Coding see bit 0.
      [1] SPE_DCHG_IRQ_EN — SPE DCHG IRQ interrupt enable. Coding see bit 0.
      [0] SPE_NIPD_IRQ_EN — SPE NIPD IRQ interrupt enable
    0x08 SPEi_IRQ_FORCINT — SPE0 Interrupt Generation by Software resetvalue={Application Reset:0x0}
      [4] TRG_SPE_RCMP — Force interrupt of SPE RCMP. Coding see bit 0.
      [3] TRG_SPE_BIS — Force interrupt of SPE BIS. Coding see bit 0.
      [2] TRG_SPE_PERR — Force interrupt of SPE PERR. Coding see bit 0.
      [1] TRG_SPE_DCHG — Force interrupt of SPE DCHG. Coding see bit 0.
      [0] TRG_SPE_NIPD — Force interrupt of SPE NIPD. This bit is cleared automatically after interrupt is released. This bit is write protected by bit RF PROT of register GTM CTRL.
    0x0C SPEi_IRQ_MODE — SPE0 Interrupt Mode Configuration Register resetvalue={Application Reset:0x0}
      [1:0] IRQ_MODE — IRQ mode selection. The interrupt modes are described in CROSSREFERENCE .
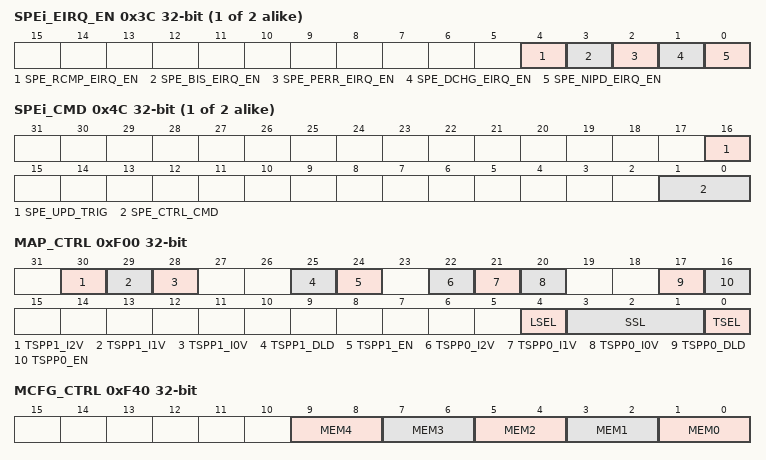
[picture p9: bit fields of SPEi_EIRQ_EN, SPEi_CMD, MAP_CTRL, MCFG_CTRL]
  0x3C SPEi_EIRQ_EN — SPE0 Error Interrupt Enable Register resetvalue={Application Reset:0x0}
    [4] SPE_RCMP_EIRQ_EN — SPE RCMP EIRQ error interrupt enable. Coding see bit 0.
    [3] SPE_BIS_EIRQ_EN — SPE BIS EIRQ error interrupt enable. Coding see bit 0.
    [2] SPE_PERR_EIRQ_EN — SPE PERR EIRQ error interrupt enable. Coding see bit 0.
    [1] SPE_DCHG_EIRQ_EN — SPE DCHG EIRQ error interrupt enable. Coding see bit 0.
    [0] SPE_NIPD_EIRQ_EN — SPE NIPD EIRQ interrupt enable
  0x40 SPEi_REV_CNT — SPE0 Input Revolution Counter resetvalue={Application Reset:0x0}
    [23:0] REV_CNT — Input signal revolution counter. The counter is running if SPE module is enabled bit SPE EN . REV CNT is incrementing if SPE PAT PTR is incrementing. REV CNT is decrementing if SPE PAT PTR is decrementing
  0x44 SPEi_REV_CMP — SPE0 Revolution Counter Compare Value resetvalue={Application Reset:0x0}
    [23:0] REV_CMP — Input signal revolution counter compare value. The interrupt SPE i RCMP is raised when the SPE i REV CNT value equals the SPE i REV CMP register. It should be noted that SPE i RCMP is only raised if an incrementation or decrementation of SPE i REV CNT is applied due to an input signal change. Any update of SPE i REV CNT or SPE i REV CMP via AEI does not raise a SPE i RCMP interrupt.
  0x48 SPEi_CTRL_STAT2 — SPE0 Control Status Register 2 resetvalue={Application Reset:0x0}
    [10:8] SPE_PAT_PTR_BWD — Pattern selector for TOM output signals in case of SPE CTRL CMD 0b01 e.g. backward direction . Index into the SPE i OUT PAT z register table in case of SPE CTRL CMD 0b01 which may be used for backward direction. Each register SPE i OUT PAT x is fixed assigned to one bit field IPx PAT of register SPE i PAT. Thus the pointer SPE i PAT PTR BWD represents an index to the selected SPE i OUT PAT x register as well as the actual detected input pattern IPx PAT. The index pointer SPE PAT PTR BWD is used if SPE CTRL CMD 160 0b01. The index pointer SPE PAT PTR is used if SPE CTRL CMD 160 160 0b00 by default .
  0x4C SPEi_CMD — SPE0 Command register resetvalue={Application Reset:0x0}
    [16] SPE_UPD_TRIG — SPE updater trigger. 1 trigger update of SPE OUT CTRL with register selected by CTR CMD multiplexer. This bit is automatically reset to 0.
    [1:0] SPE_CTRL_CMD — SPE control command
0xF00 MAP_CTRL — MAP Control Register resetvalue={Application Reset:0x0}
  [30] TSPP1_I2V — Disable of TSPP1 TIM0 CHz 48 input line
  [29] TSPP1_I1V — Disable of TSPP1 TIM0 CHy 48 input line
  [28] TSPP1_I0V — Disable of TSPP1 TIM0 CHx 48 input line
  [25] TSPP1_DLD — DIR level definition bit
  [24] TSPP1_EN — Enable of TSPP1 subunit
  [22] TSPP0_I2V — Disable of TSPP0 TIM0 CHz 48 input line
  [21] TSPP0_I1V — Disable of TSPP0 TIM0 CHy 48 input line
  [20] TSPP0_I0V — Disable of TSPP0 TIM0 CHx 48 input line
  [17] TSPP0_DLD — DIR level definition bit
  [16] TSPP0_EN — Enable of TSPP0 subunit
  [4] LSEL — TIM0 IN6 input level selection
  [3:1] SSL — STATE signal output select
  [0] TSEL — TRIGGER signal output select
0xF40 MCFG_CTRL — MCFG Memory Layout Configuration Register resetvalue={Application Reset:0x0}
  [2n+1:2n] MEM{n} (n=0..4) — Configure Memory pages for MCS instance MCS9
